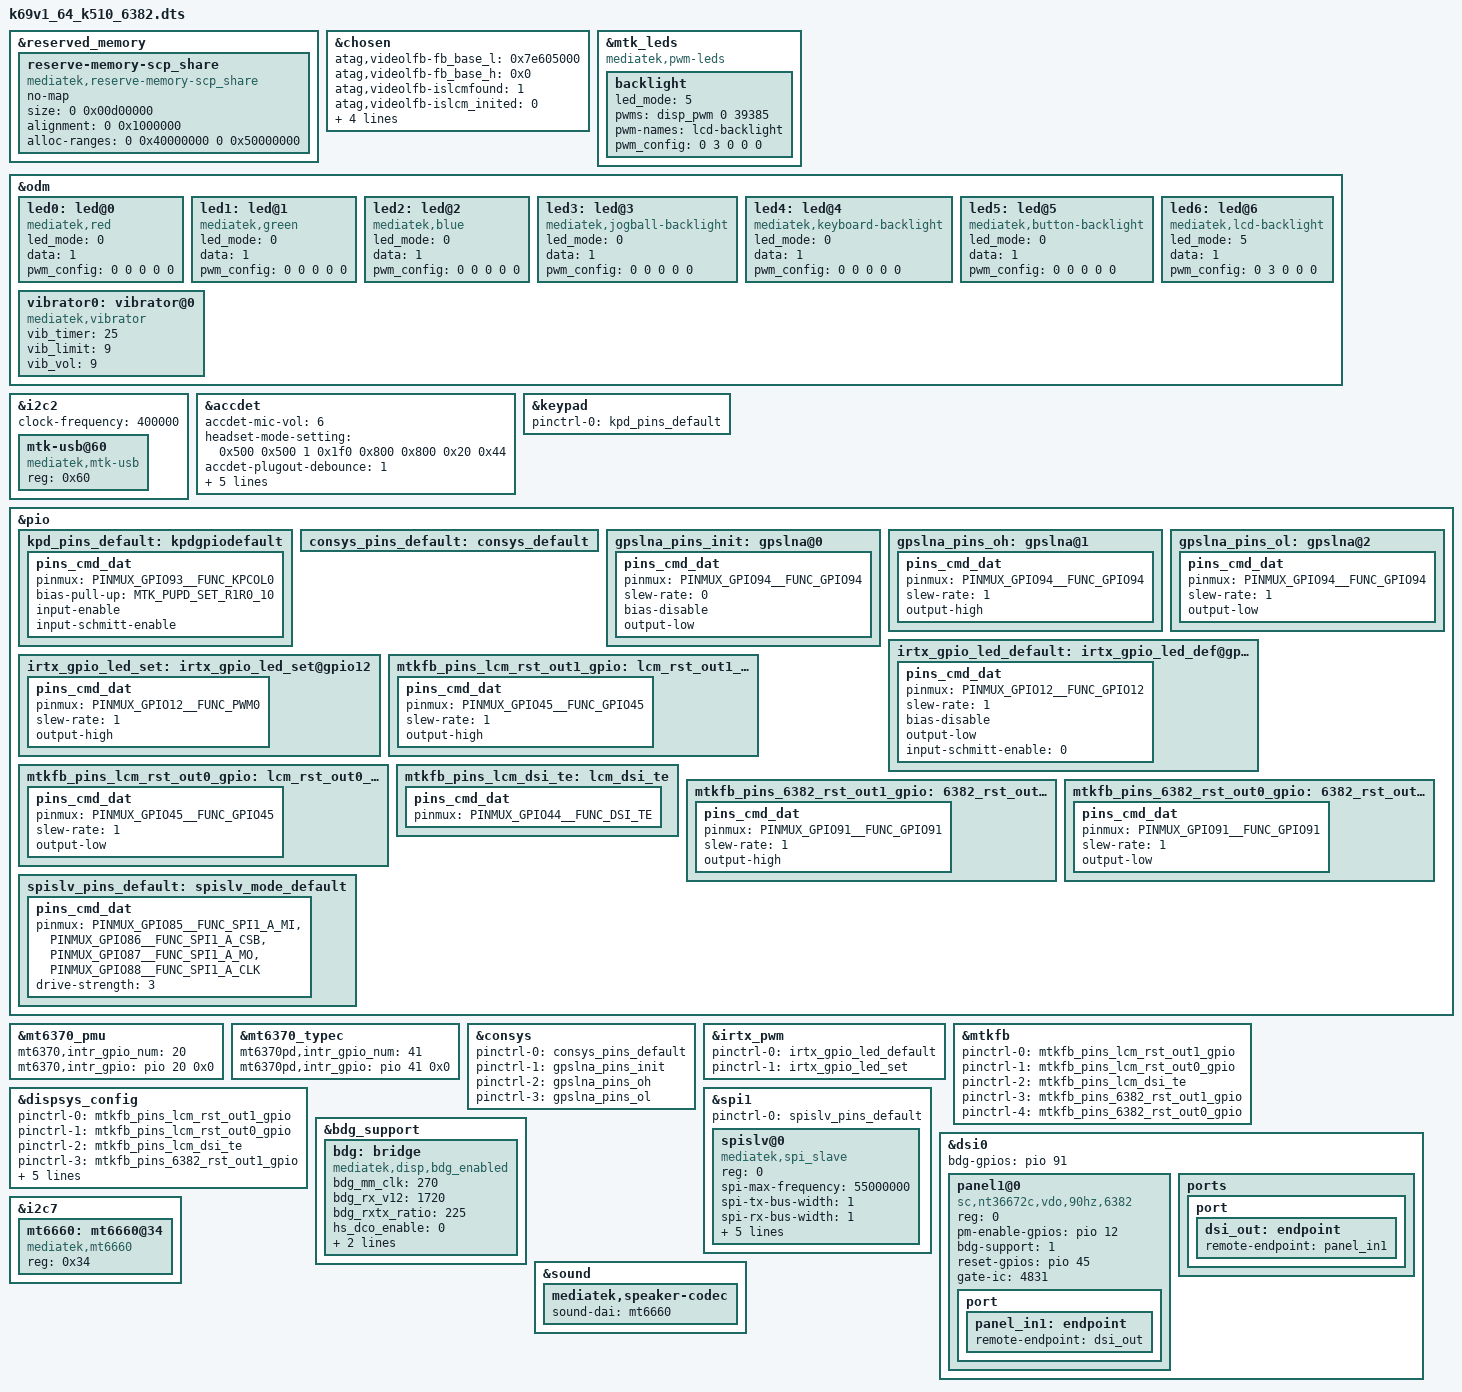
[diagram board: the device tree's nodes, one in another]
// SPDX-License-Identifier: GPL-2.0
/*
 * Copyright (c) 2019 MediaTek Inc.
 */

/dts-v1/;
/plugin/;
#include <dt-bindings/interrupt-controller/irq.h>
#include <dt-bindings/interrupt-controller/arm-gic.h>
#include <dt-bindings/pinctrl/mt6768-pinfunc.h>

&reserved_memory {
	reserve-memory-scp_share {
		compatible = "mediatek,reserve-memory-scp_share";
		no-map;
		size = <0 0x00d00000>;
		alignment = <0 0x1000000>;
		alloc-ranges = <0 0x40000000 0 0x50000000>;
	};
};

/* chosen */
&chosen {

	atag,videolfb-fb_base_l = <0x7e605000>;
	atag,videolfb-fb_base_h = <0x0>;
	atag,videolfb-islcmfound = <1>;
	atag,videolfb-islcm_inited = <0>;
	atag,videolfb-fps= <6000>;
	atag,videolfb-vramSize= <0x017e8000>;
	atag,videolfb-lcmname=
		"sc_nt36672c_vdo_90hz_6382_drv";
};

&mtk_leds {
	compatible = "mediatek,pwm-leds";
	backlight {
		led_mode = <5>;
		pwms = <&disp_pwm 0 39385>;
		pwm-names = "lcd-backlight";
		pwm_config = <0 3 0 0 0>;
	};
};

&odm {
	led0:led@0 {
		compatible = "mediatek,red";
		led_mode = <0>;
		data = <1>;
		pwm_config = <0 0 0 0 0>;
	};
	led1:led@1 {
		compatible = "mediatek,green";
		led_mode = <0>;
		data = <1>;
		pwm_config = <0 0 0 0 0>;
	};
	led2:led@2 {
		compatible = "mediatek,blue";
		led_mode = <0>;
		data = <1>;
		pwm_config = <0 0 0 0 0>;
	};
	led3:led@3 {
		compatible = "mediatek,jogball-backlight";
		led_mode = <0>;
		data = <1>;
		pwm_config = <0 0 0 0 0>;
	};
	led4:led@4 {
		compatible = "mediatek,keyboard-backlight";
		led_mode = <0>;
		data = <1>;
		pwm_config = <0 0 0 0 0>;
	};
	led5:led@5 {
		compatible = "mediatek,button-backlight";
		led_mode = <0>;
		data = <1>;
		pwm_config = <0 0 0 0 0>;
	};
	led6:led@6 {
		compatible = "mediatek,lcd-backlight";
		led_mode = <5>;
		data = <1>;
		pwm_config = <0 3 0 0 0>;
	};
	vibrator0:vibrator@0 {
		compatible = "mediatek,vibrator";
		vib_timer = <25>;
		vib_limit = <9>;
		vib_vol= <9>;
	};
};

&i2c2 {
	clock-frequency = <400000>;

	mtk-usb@60 {
		compatible = "mediatek,mtk-usb";
		reg = <0x60>;
		status = "okay";
	};
};

/* accdet start */
&accdet {
	/* accdet micbias voltage: 0x07,2.7v;0x05,2.5v;0x02,1.9v */
	accdet-mic-vol = <6>;
	headset-mode-setting = <0x500 0x500 1 0x1f0 0x800 0x800 0x20 0x44>;
	accdet-plugout-debounce = <1>;
	/*1:ACC mode, 2:low cost without in bias, 6:low cost with in bias*/
	accdet-mic-mode = <1>;
	/* eint_level_trigger: 8,LEVEL_LOW(DEF) ;4,LV_HIGH;others,LV_LOW */
	headset-eint-level-pol = <8>;
	/*0--MD_MAX--UP_MAX--DW_MAX*/
	headset-three-key-threshold = <0 80 220 400>;
	headset-three-key-threshold-CDD = <0 121 192 600>;
	/*0--MD_MAX--VOICE_MAX--UP_MAX--DW_MAX*/
	headset-four-key-threshold = <0 58 121 192 400>;
	status = "okay";
};
/* accdet end */

/* keypad start */
&keypad {
	pinctrl-names = "default";
	pinctrl-0 = <&kpd_pins_default>;
};

&pio {
	kpd_pins_default: kpdgpiodefault {
		pins_cmd_dat {
			pinmux = <PINMUX_GPIO93__FUNC_KPCOL0>;
			bias-pull-up = <MTK_PUPD_SET_R1R0_10>;
			input-enable;
			input-schmitt-enable;
		};
	};
};
/* keypad end */

&mt6370_pmu {
	mt6370,intr_gpio_num = <20>; /* direct defined GPIO num */
	mt6370,intr_gpio = <&pio 20 0x0>;
};
&mt6370_typec {
	mt6370pd,intr_gpio_num = <41>; /* direct defined GPIO num */
	mt6370pd,intr_gpio = <&pio 41 0x0>;
};

/* CONSYS GPIO standardization */
&pio {
	consys_pins_default: consys_default {
	};
	gpslna_pins_init: gpslna@0 {
		pins_cmd_dat {
			pinmux = <PINMUX_GPIO94__FUNC_GPIO94>;
			slew-rate = <0>;
			bias-disable;
			output-low;
		};
	};
	gpslna_pins_oh: gpslna@1 {
		pins_cmd_dat {
			pinmux = <PINMUX_GPIO94__FUNC_GPIO94>;
			slew-rate = <1>;
			output-high;
		};
	};
	gpslna_pins_ol: gpslna@2 {
		pins_cmd_dat {
			pinmux = <PINMUX_GPIO94__FUNC_GPIO94>;
			slew-rate = <1>;
			output-low;
		};
	};
};
&consys {
	pinctrl-names = "default", "gps_lna_state_init",
		"gps_lna_state_oh", "gps_lna_state_ol";
	pinctrl-0 = <&consys_pins_default>;
	pinctrl-1 = <&gpslna_pins_init>;
	pinctrl-2 = <&gpslna_pins_oh>;
	pinctrl-3 = <&gpslna_pins_ol>;
	status = "okay";
};
/* CONSYS end */

/* IRTX GPIO Start */
&irtx_pwm {
	pinctrl-names = "irtx_gpio_led_default", "irtx_gpio_led_set";
	pinctrl-0 = <&irtx_gpio_led_default>;
	pinctrl-1 = <&irtx_gpio_led_set>;
	status = "okay";
};
&pio {
	/* IRTX GPIO Settings -Start */
	/* default: GPIO0, output, high */
	irtx_gpio_led_default:irtx_gpio_led_def@gpio12 {
		pins_cmd_dat {
			pinmux = <PINMUX_GPIO12__FUNC_GPIO12>;
			slew-rate = <1>;
			bias-disable;
			output-low;
			input-schmitt-enable = <0>;
		};
	};

	irtx_gpio_led_set:irtx_gpio_led_set@gpio12 {
		pins_cmd_dat {
			pinmux = <PINMUX_GPIO12__FUNC_PWM0>;
			slew-rate = <1>;
			output-high;
		};
	};
}; /* IRTX GPIO Settings -End */

/* DISPSYS GPIO standardization */
&pio {
	mtkfb_pins_lcm_rst_out1_gpio: lcm_rst_out1_gpio {
		pins_cmd_dat {
			pinmux = <PINMUX_GPIO45__FUNC_GPIO45>;
			slew-rate = <1>;
			output-high;
		};
	};

	mtkfb_pins_lcm_rst_out0_gpio: lcm_rst_out0_gpio {
		pins_cmd_dat {
			pinmux = <PINMUX_GPIO45__FUNC_GPIO45>;
			slew-rate = <1>;
			output-low;
		};
	};

	mtkfb_pins_lcm_dsi_te: lcm_dsi_te {
		pins_cmd_dat {
			pinmux = <PINMUX_GPIO44__FUNC_DSI_TE>;
		};
	};

	mtkfb_pins_6382_rst_out1_gpio: 6382_rst_out1_gpio {
		pins_cmd_dat {
			pinmux = <PINMUX_GPIO91__FUNC_GPIO91>;
			slew-rate = <1>;
			output-high;
		};
	};

	mtkfb_pins_6382_rst_out0_gpio: 6382_rst_out0_gpio {
		pins_cmd_dat {
			pinmux = <PINMUX_GPIO91__FUNC_GPIO91>;
			slew-rate = <1>;
			output-low;
		};
	};
};

&mtkfb {
	pinctrl-names =
		"lcm_rst_out1_gpio", "lcm_rst_out0_gpio",
		"mode_te_te", "6382_rst_out1_gpio", "6382_rst_out0_gpio";
	pinctrl-0 = <&mtkfb_pins_lcm_rst_out1_gpio>;
	pinctrl-1 = <&mtkfb_pins_lcm_rst_out0_gpio>;
	pinctrl-2 = <&mtkfb_pins_lcm_dsi_te>;
	pinctrl-3 = <&mtkfb_pins_6382_rst_out1_gpio>;
	pinctrl-4 = <&mtkfb_pins_6382_rst_out0_gpio>;
	status = "okay";
};

&dispsys_config {
	pinctrl-names =
		"lcm_rst_out1_gpio", "lcm_rst_out0_gpio",
		"mode_te_te", "6382_rst_out1_gpio", "6382_rst_out0_gpio";
	pinctrl-0 = <&mtkfb_pins_lcm_rst_out1_gpio>;
	pinctrl-1 = <&mtkfb_pins_lcm_rst_out0_gpio>;
	pinctrl-2 = <&mtkfb_pins_lcm_dsi_te>;
	pinctrl-3 = <&mtkfb_pins_6382_rst_out1_gpio>;
	pinctrl-4 = <&mtkfb_pins_6382_rst_out0_gpio>;
	status = "okay";

	helper-value = <0>, /*MTK_DRM_OPT_STAGE*/
				<1>, /*MTK_DRM_OPT_USE_CMDQ*/
				<1>, /*MTK_DRM_OPT_USE_M4U*/
				<1>, /*MTK_DRM_OPT_MMQOS_SUPPORT*/
				<1>, /*MTK_DRM_OPT_MMDVFS_SUPPORT*/
				<0>, /*MTK_DRM_OPT_SODI_SUPPORT*/
				<1>, /*MTK_DRM_OPT_IDLE_MGR*/
				<0>, /*MTK_DRM_OPT_IDLEMGR_SWTCH_DECOUPLE*/
				<1>, /*MTK_DRM_OPT_IDLEMGR_BY_REPAINT*/
				<0>, /*MTK_DRM_OPT_IDLEMGR_ENTER_ULPS*/
				<0>, /*MTK_DRM_OPT_IDLEMGR_KEEP_LP11*/
				<1>, /*MTK_DRM_OPT_DYNAMIC_RDMA_GOLDEN_SETTING*/
				<1>, /*MTK_DRM_OPT_IDLEMGR_DISABLE_ROUTINE_IRQ*/
				<0>, /*MTK_DRM_OPT_MET_LOG*/
				<1>, /*MTK_DRM_OPT_USE_PQ*/
				<1>, /*MTK_DRM_OPT_ESD_CHECK_RECOVERY*/
				<1>, /*MTK_DRM_OPT_ESD_CHECK_SWITCH*/
				<1>, /*MTK_DRM_OPT_PRESENT_FENCE*/
				<0>, /*MTK_DRM_OPT_RDMA_UNDERFLOW_AEE*/
				<1>, /*MTK_DRM_OPT_DSI_UNDERRUN_AEE*/
				<1>, /*MTK_DRM_OPT_HRT*/
				<1>, /*MTK_DRM_OPT_HRT_MODE*/
				<0>, /*MTK_DRM_OPT_DELAYED_TRIGGER*/
				<1>, /*MTK_DRM_OPT_OVL_EXT_LAYER*/
				<0>, /*MTK_DRM_OPT_AOD*/
				<1>, /*MTK_DRM_OPT_RPO*/
				<0>, /*MTK_DRM_OPT_DUAL_PIPE*/
				<0>, /*MTK_DRM_OPT_DC_BY_HRT*/
				<0>, /*MTK_DRM_OPT_OVL_WCG*/
				<0>, /*MTK_DRM_OPT_OVL_SBCH*/
				<1>, /*MTK_DRM_OPT_COMMIT_NO_WAIT_VBLANK*/
				<0>, /*MTK_DRM_OPT_MET*/
				<0>, /*MTK_DRM_OPT_REG_PARSER_RAW_DUMP*/
				<0>, /*MTK_DRM_OPT_VP_PQ*/
				<0>, /*MTK_DRM_OPT_GAME_PQ*/
				<0>, /*MTK_DRM_OPT_MMPATH*/
				<0>, /*MTK_DRM_OPT_HBM*/
				<0>, /*MTK_DRM_OPT_VDS_PATH_SWITCH*/
				<0>, /*MTK_DRM_OPT_LAYER_REC*/
				<1>, /*MTK_DRM_OPT_CLEAR_LAYER*/
				<0>, /*MTK_DRM_OPT_LFR*/
				<0>, /*MTK_DRM_OPT_SF_PF*/
				<1>, /*MTK_DRM_OPT_DYN_MIPI_CHANGE*/
				<0>, /*MTK_DRM_OPT_PRIM_DUAL_PIPE*/
				<0>, /*MTK_DRM_OPT_MSYNC2_0*/
				<0>, /*MTK_DRM_OPT_MML_PRIMARY*/
				<0>, /*MTK_DRM_OPT_DUAL_TE*/
				<0>, /*MTK_DRM_OPT_VIRTUAL_DISP*/
				<0>, /*MTK_DRM_OPT_RES_SWITCH*/
				<1>; /*MTK_DRM_OPT_SHARE_SRAM*/
};

&spi1 {
	status = "okay";
	#address-cells = <1>;
	#size-cells = <0>;
	pinctrl-names = "default";
	pinctrl-0 = <&spislv_pins_default>;

	spislv@0 {
		compatible = "mediatek,spi_slave";
		reg = <0>;
		spi-max-frequency = <55000000>;
		spi-tx-bus-width = <1>;
		spi-rx-bus-width = <1>;
		low-speed-tick-delay = /bits/ 8 <4>;
		low-speed-early-trans = /bits/ 8 <0>;
		high-speed-tick-delay = /bits/ 8 <2>;
		high-speed-early-trans = /bits/ 8 <0>;
		slave-drive-strength = /bits/ 8 <3>;
	};
};

&pio {
	spislv_pins_default: spislv_mode_default {
		pins_cmd_dat {
			pinmux = <PINMUX_GPIO85__FUNC_SPI1_A_MI>,
				<PINMUX_GPIO86__FUNC_SPI1_A_CSB>,
				<PINMUX_GPIO87__FUNC_SPI1_A_MO>,
				<PINMUX_GPIO88__FUNC_SPI1_A_CLK>;
			drive-strength = <3>;
		};
	};
};

&dsi0 {
	status = "okay";
	#address-cells = <1>;
	#size-cells = <0>;
	bdg-gpios = <&pio 91 0>;
	panel1@0 {
		compatible = "sc,nt36672c,vdo,90hz,6382";
		reg = <0>;
		pm-enable-gpios = <&pio 12 0>;
		bdg-support=<1>;
		reset-gpios = <&pio 45 0>;
		gate-ic = <4831>;
		pinctrl-names = "default";
		port {
			panel_in1: endpoint {
				remote-endpoint = <&dsi_out>;
			};
		};
	};
	ports {
		port {
			dsi_out: endpoint {
				remote-endpoint = <&panel_in1>;
			};
		};
	};
};

&bdg_support {
	bdg: bridge {
		compatible = "mediatek,disp,bdg_enabled";
		bdg_mm_clk = <270>;
		bdg_rx_v12 = <1720>;
		bdg_rxtx_ratio = <225>;
		hs_dco_enable = <0>;
		lp_tx_l023_enable = <0>;
		g_mode_enable = <0>;
	};
};

&i2c7 {
	mt6660: mt6660@34 {
		compatible = "mediatek,mt6660";
		#sound-dai-cells = <0>;
		reg = <0x34>;
		status = "okay";
	};
};

&sound {
	mediatek,speaker-codec {
		sound-dai = <&mt6660>;
	};
};

/* DISPSYS GPIO standardization end*/

#include <k69v1_64_k510_6382/cust.dtsi>
#include "mediatek/cust_mt6768_camera.dtsi"
#include "mediatek/cust_mt6768_6382_touch.dtsi"
/*End of this file, DO NOT ADD ANYTHING HERE*/
